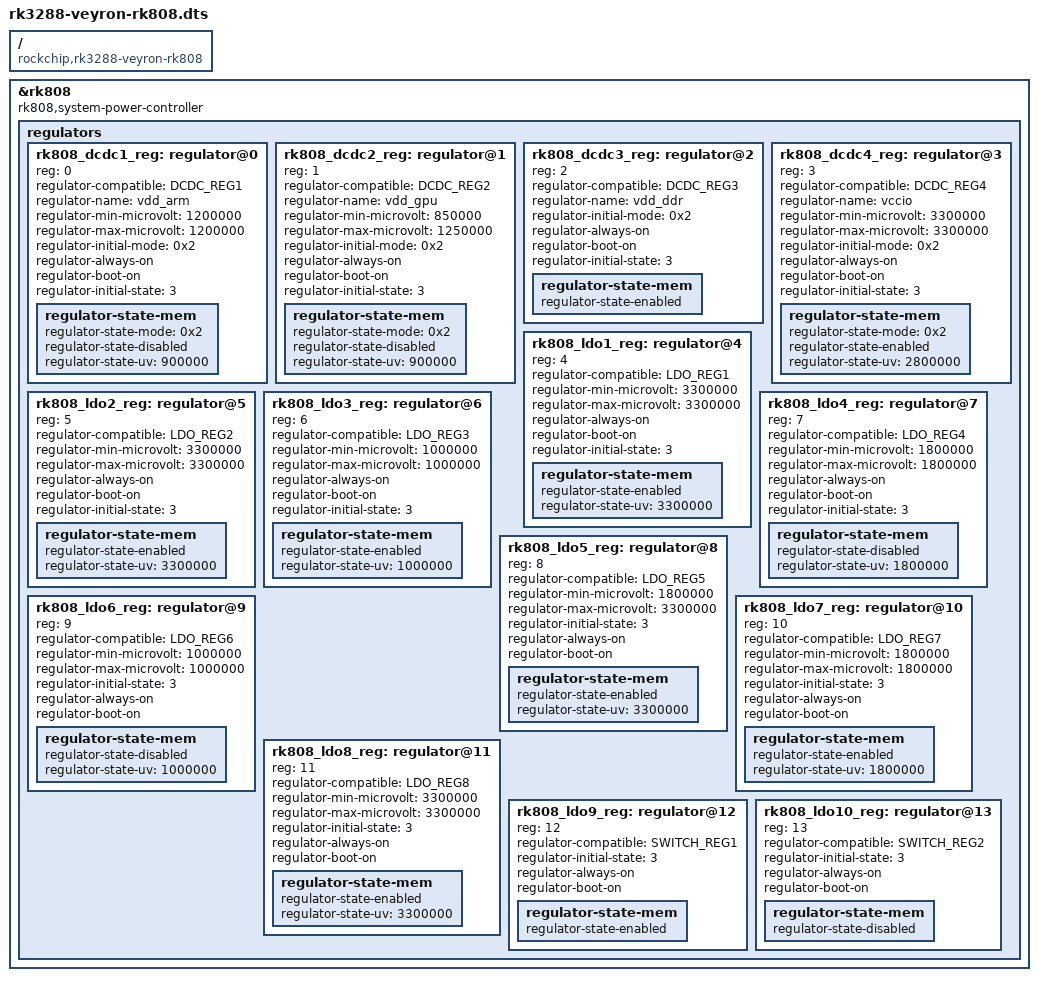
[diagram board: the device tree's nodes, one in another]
/*
 * This program is free software; you can redistribute it and/or modify
 * it under the terms of the GNU General Public License as published by
 * the Free Software Foundation; either version 2 of the License, or
 * (at your option) any later version.
 *
 * This program is distributed in the hope that it will be useful,
 * but WITHOUT ANY WARRANTY; without even the implied warranty of
 * MERCHANTABILITY or FITNESS FOR A PARTICULAR PURPOSE.  See the
 * GNU General Public License for more details.
 */

/dts-v1/;
#include "rk3288-veyron.dtsi"

/ {
	compatible = "rockchip,rk3288-veyron-rk808", "rockchip,veyron";
	
};
&rk808 {
		//compatible = "rockchip,rk808";
		rk808,system-power-controller;
		regulators {
			#address-cells = <1>;
			#size-cells = <0>;

			rk808_dcdc1_reg: regulator@0 {
				reg = <0>;
				regulator-compatible = "DCDC_REG1";
				regulator-name = "vdd_arm";
				regulator-min-microvolt = <1200000>;
				regulator-max-microvolt = <1200000>;
				regulator-initial-mode = <0x2>;
				regulator-always-on;
				regulator-boot-on;
				regulator-initial-state = <3>;
				regulator-state-mem {
					regulator-state-mode = <0x2>;
					regulator-state-disabled;//disabled
					regulator-state-uv = <900000>;
				};
			};

			rk808_dcdc2_reg: regulator@1 {
				reg = <1>;
				regulator-compatible = "DCDC_REG2";
				regulator-name = "vdd_gpu";
				regulator-min-microvolt = <850000>;
				regulator-max-microvolt = <1250000>;
				regulator-initial-mode = <0x2>;
				regulator-always-on;
				regulator-boot-on;
				regulator-initial-state = <3>;
				regulator-state-mem {
					regulator-state-mode = <0x2>;
					regulator-state-disabled;
					regulator-state-uv = <900000>;
				};
			};

			rk808_dcdc3_reg: regulator@2 {
				reg = <2>;
				regulator-compatible = "DCDC_REG3";
				regulator-name = "vdd_ddr";
				regulator-initial-mode = <0x2>;
				regulator-always-on;
				regulator-boot-on;
				regulator-initial-state = <3>;
				regulator-state-mem {
					regulator-state-enabled;
				};
			};

			rk808_dcdc4_reg: regulator@3 {
				reg = <3>;
				regulator-compatible = "DCDC_REG4";
				regulator-name = "vccio";
				regulator-min-microvolt = <3300000>;
				regulator-max-microvolt = <3300000>;
				regulator-initial-mode = <0x2>;
				regulator-always-on;
				regulator-boot-on;
				regulator-initial-state = <3>;
				regulator-state-mem {
					regulator-state-mode = <0x2>;
					regulator-state-enabled;
					regulator-state-uv = <2800000>;
				};
			};

			rk808_ldo1_reg: regulator@4 {
				reg = <4>;
				regulator-compatible = "LDO_REG1";
				regulator-min-microvolt = <3300000>;
				regulator-max-microvolt = <3300000>;
				regulator-always-on;
				regulator-boot-on;
				regulator-initial-state = <3>;
				regulator-state-mem {
					regulator-state-enabled;
					regulator-state-uv = <3300000>;
				};
			};

			rk808_ldo2_reg: regulator@5 {
				reg = <5>;
				regulator-compatible = "LDO_REG2";
				regulator-min-microvolt = <3300000>;
				regulator-max-microvolt = <3300000>;
				regulator-always-on;
				regulator-boot-on;
				regulator-initial-state = <3>;
				regulator-state-mem {
					regulator-state-enabled;
					regulator-state-uv = <3300000>;
				};
			};

			rk808_ldo3_reg: regulator@6 {
				reg = <6>;
				regulator-compatible = "LDO_REG3";
				regulator-min-microvolt = <1000000>;
				regulator-max-microvolt = <1000000>;
				regulator-always-on;
				regulator-boot-on;
				regulator-initial-state = <3>;
				regulator-state-mem {
					regulator-state-enabled;
					regulator-state-uv = <1000000>;
				};
			};

			rk808_ldo4_reg: regulator@7{
				reg = <7>;
				regulator-compatible = "LDO_REG4";
				regulator-min-microvolt = <1800000>;
				regulator-max-microvolt = <1800000>;
				regulator-always-on;
				regulator-boot-on;
				regulator-initial-state = <3>;
				regulator-state-mem {
					regulator-state-disabled;
					regulator-state-uv = <1800000>;
				};
			};

			rk808_ldo5_reg: regulator@8{
				reg = <8>;
				regulator-compatible = "LDO_REG5";
				regulator-min-microvolt = <1800000>;
				regulator-max-microvolt = <3300000>;
				regulator-initial-state = <3>;
				regulator-always-on;
				regulator-boot-on;
				regulator-state-mem {
					regulator-state-enabled;
					regulator-state-uv = <3300000>;
				};
			};

			rk808_ldo6_reg: regulator@9{
				reg = <9>;
				regulator-compatible = "LDO_REG6";
				regulator-min-microvolt = <1000000>;
				regulator-max-microvolt = <1000000>;
				regulator-initial-state = <3>;
				regulator-always-on;
				regulator-boot-on;
				regulator-state-mem {
					regulator-state-disabled;
					regulator-state-uv = <1000000>;
				};
			};

			rk808_ldo7_reg: regulator@10 {
				reg = <10>;
				regulator-compatible = "LDO_REG7";
				regulator-min-microvolt = <1800000>;
				regulator-max-microvolt = <1800000>;
				regulator-initial-state = <3>;
				regulator-always-on;
				regulator-boot-on;
				regulator-state-mem {
					regulator-state-enabled;
					regulator-state-uv = <1800000>;
				};
			};

			rk808_ldo8_reg: regulator@11{
				reg = <11>;
				regulator-compatible = "LDO_REG8";
				regulator-min-microvolt = <3300000>;
				regulator-max-microvolt = <3300000>;
				regulator-initial-state = <3>;
				regulator-always-on;
				regulator-boot-on;
				regulator-state-mem {
					regulator-state-enabled;
					regulator-state-uv = <3300000>;
				};
			};

			rk808_ldo9_reg: regulator@12{
				reg = <12>;
				regulator-compatible = "SWITCH_REG1";
				regulator-initial-state = <3>;
				regulator-always-on;
				regulator-boot-on;
				regulator-state-mem {
					regulator-state-enabled;
				};
			};

			rk808_ldo10_reg: regulator@13{
				reg = <13>;
				regulator-compatible = "SWITCH_REG2";
				regulator-initial-state = <3>;
				regulator-always-on;
				regulator-boot-on;
				regulator-state-mem {
					regulator-state-disabled;
				};
			};

		};
	};
